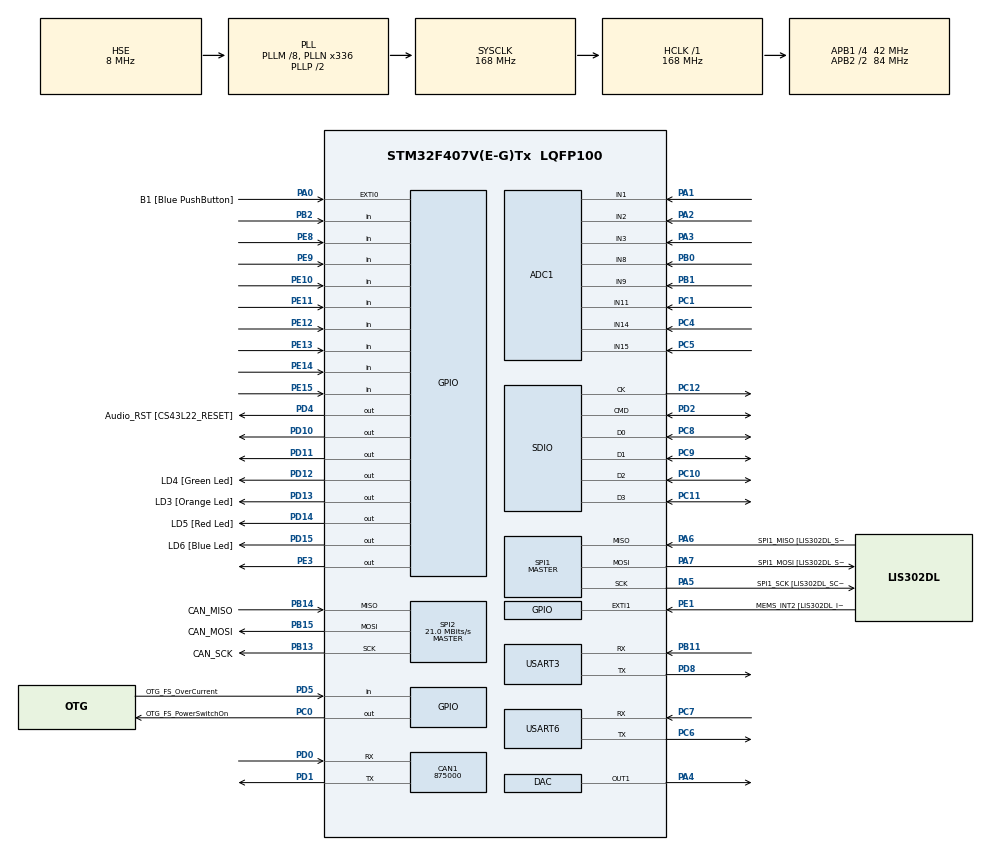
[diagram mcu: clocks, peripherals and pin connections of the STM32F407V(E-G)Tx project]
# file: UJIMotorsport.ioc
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ADC1.Channel-16\#ChannelRegularConversion=ADC_CHANNEL_1
ADC1.Channel-17\#ChannelRegularConversion=ADC_CHANNEL_2
ADC1.Channel-18\#ChannelRegularConversion=ADC_CHANNEL_3
ADC1.Channel-19\#ChannelRegularConversion=ADC_CHANNEL_8
ADC1.Channel-20\#ChannelRegularConversion=ADC_CHANNEL_9
ADC1.Channel-21\#ChannelRegularConversion=ADC_CHANNEL_11
ADC1.Channel-22\#ChannelRegularConversion=ADC_CHANNEL_14
ADC1.Channel-23\#ChannelRegularConversion=ADC_CHANNEL_15
ADC1.Channel-24\#ChannelRegularConversion=ADC_CHANNEL_TEMPSENSOR
ADC1.Channel-25\#ChannelRegularConversion=ADC_CHANNEL_VREFINT
ADC1.Channel-26\#ChannelRegularConversion=ADC_CHANNEL_VBAT
ADC1.ContinuousConvMode=ENABLE
ADC1.DMAContinuousRequests=ENABLE
ADC1.NbrOfConversion=11
ADC1.NbrOfConversionFlag=1
ADC1.Rank-16\#ChannelRegularConversion=1
ADC1.Rank-17\#ChannelRegularConversion=2
ADC1.Rank-18\#ChannelRegularConversion=3
ADC1.Rank-19\#ChannelRegularConversion=4
ADC1.Rank-20\#ChannelRegularConversion=5
ADC1.Rank-21\#ChannelRegularConversion=6
ADC1.Rank-22\#ChannelRegularConversion=7
ADC1.Rank-23\#ChannelRegularConversion=8
ADC1.Rank-24\#ChannelRegularConversion=9
ADC1.Rank-25\#ChannelRegularConversion=10
ADC1.Rank-26\#ChannelRegularConversion=11
ADC1.SamplingTime-16\#ChannelRegularConversion=ADC_SAMPLETIME_3CYCLES
ADC1.SamplingTime-17\#ChannelRegularConversion=ADC_SAMPLETIME_3CYCLES
ADC1.SamplingTime-18\#ChannelRegularConversion=ADC_SAMPLETIME_3CYCLES
ADC1.SamplingTime-19\#ChannelRegularConversion=ADC_SAMPLETIME_3CYCLES
ADC1.SamplingTime-20\#ChannelRegularConversion=ADC_SAMPLETIME_3CYCLES
ADC1.SamplingTime-21\#ChannelRegularConversion=ADC_SAMPLETIME_3CYCLES
ADC1.SamplingTime-22\#ChannelRegularConversion=ADC_SAMPLETIME_3CYCLES
ADC1.SamplingTime-23\#ChannelRegularConversion=ADC_SAMPLETIME_3CYCLES
ADC1.SamplingTime-24\#ChannelRegularConversion=ADC_SAMPLETIME_3CYCLES
ADC1.SamplingTime-25\#ChannelRegularConversion=ADC_SAMPLETIME_3CYCLES
ADC1.SamplingTime-26\#ChannelRegularConversion=ADC_SAMPLETIME_3CYCLES
ADC1.ScanConvMode=ENABLE
ADC1.master=1
CAN1.CalculateBaudRate=875000
CAN1.CalculateTimeBit=1142
CAN1.CalculateTimeQuantum=380.95238095238096
Dma.ADC1.0.Direction=DMA_PERIPH_TO_MEMORY
Dma.ADC1.0.FIFOMode=DMA_FIFOMODE_DISABLE
Dma.ADC1.0.Instance=DMA2_Stream0
Dma.ADC1.0.MemDataAlignment=DMA_MDATAALIGN_HALFWORD
Dma.ADC1.0.MemInc=DMA_MINC_ENABLE
Dma.ADC1.0.Mode=DMA_CIRCULAR
Dma.ADC1.0.PeriphDataAlignment=DMA_PDATAALIGN_HALFWORD
Dma.ADC1.0.PeriphInc=DMA_PINC_DISABLE
Dma.ADC1.0.Priority=DMA_PRIORITY_LOW
Dma.Request0=ADC1
FATFS.BSP.number=1
FATFS0.BSP.STBoard=false
FATFS0.BSP.api=Unknown
FATFS0.BSP.i2caddr=0
FATFS0.BSP.instance=PB2
FATFS0.BSP.ip=GPIO
FATFS0.BSP.mode=Input
FATFS0.BSP.name=Detect_SDIO
FATFS0.BSP.solution=PB2
FREERTOS.INCLUDE_vTaskDelayUntil=1
FREERTOS.Tasks01=defaultTask,0,128,StartDefaultTask,Default,NULL,Dynamic,NULL,NULL
FREERTOS.configENABLE_FPU=1
FREERTOS.configTOTAL_HEAP_SIZE=32768
FREERTOS.configUSE_NEWLIB_REENTRANT=1
Mcu.Family=STM32F4
Mcu.Name=STM32F407V(E-G)Tx
Mcu.Package=LQFP100
NVIC.DMA2_Stream0_IRQn=true\:5\:0\:false\:false\:true\:true\:false\:true
NVIC.PriorityGroup=NVIC_PRIORITYGROUP_4
NVIC.TIM6_DAC_IRQn=true\:15\:0\:false\:false\:true\:false\:false\:true
NVIC.TimeBase=TIM6_DAC_IRQn
NVIC.TimeBaseIP=TIM6
PA0-WKUP.GPIO_Label=B1 [Blue PushButton]
PA0-WKUP.GPIO_ModeDefaultEXTI=GPIO_MODE_EVT_RISING
PA0-WKUP.GPIO_PuPd=GPIO_NOPULL
PA0-WKUP.Signal=GPXTI0
PA1.Signal=ADCx_IN1
PA10.GPIO_Label=OTG_FS_ID
PA10.GPIO_Mode=GPIO_MODE_AF_PP
PA10.GPIO_PuPd=GPIO_NOPULL
PA10.GPIO_Speed=GPIO_SPEED_FREQ_LOW
PA10.Signal=USB_OTG_FS_ID
PA11.GPIO_Label=OTG_FS_DM
PA11.GPIO_Mode=GPIO_MODE_AF_PP
PA11.GPIO_PuPd=GPIO_NOPULL
PA11.GPIO_Speed=GPIO_SPEED_FREQ_LOW
PA11.Signal=USB_OTG_FS_DM
PA12.GPIO_Label=OTG_FS_DP
PA12.GPIO_Mode=GPIO_MODE_AF_PP
PA12.GPIO_PuPd=GPIO_NOPULL
PA12.GPIO_Speed=GPIO_SPEED_FREQ_LOW
PA12.Signal=USB_OTG_FS_DP
PA13.GPIO_Label=SWDIO
PA13.Mode=Serial_Wire
PA13.Signal=SYS_JTMS-SWDIO
PA14.GPIO_Label=SWCLK
PA14.Mode=Serial_Wire
PA14.Signal=SYS_JTCK-SWCLK
PA2.Signal=ADCx_IN2
PA3.Signal=ADCx_IN3
PA4.Signal=COMP_DAC1_group
PA5.GPIO_Label=SPI1_SCK [LIS302DL_SCL/SPC]
PA5.GPIO_Mode=GPIO_MODE_AF_PP
PA5.GPIO_PuPd=GPIO_NOPULL
PA5.GPIO_Speed=GPIO_SPEED_FREQ_LOW
PA5.Mode=Full_Duplex_Master
PA5.Signal=SPI1_SCK
PA6.GPIO_Label=SPI1_MISO [LIS302DL_SDO]
PA6.GPIO_Mode=GPIO_MODE_AF_PP
PA6.GPIO_PuPd=GPIO_NOPULL
PA6.GPIO_Speed=GPIO_SPEED_FREQ_LOW
PA6.Mode=Full_Duplex_Master
PA6.Signal=SPI1_MISO
PA7.GPIO_Label=SPI1_MOSI [LIS302DL_SDA/SDI/SDO]
PA7.GPIO_Mode=GPIO_MODE_AF_PP
PA7.GPIO_PuPd=GPIO_NOPULL
PA7.GPIO_Speed=GPIO_SPEED_FREQ_LOW
PA7.Mode=Full_Duplex_Master
PA7.Signal=SPI1_MOSI
PA9.GPIO_Label=VBUS_FS
PA9.GPIO_Mode=GPIO_MODE_INPUT
PA9.GPIO_PuPd=GPIO_NOPULL
PA9.Signal=USB_OTG_FS_VBUS
PB0.Signal=ADCx_IN8
PB1.Signal=ADCx_IN9
PB10.GPIO_Label=CLK_IN [MP45DT02_CLK]
PB10.GPIO_Mode=GPIO_MODE_AF_PP
PB10.GPIO_PuPd=GPIO_NOPULL
PB10.GPIO_Speed=GPIO_SPEED_FREQ_LOW
PB10.Signal=I2S2_CK
PB11.Mode=Asynchronous
PB11.Signal=USART3_RX
PB13.GPIO_Label=CAN_SCK
PB13.Mode=Full_Duplex_Master
PB13.Signal=SPI2_SCK
PB14.GPIO_Label=CAN_MISO
PB14.Mode=Full_Duplex_Master
PB14.Signal=SPI2_MISO
PB15.GPIO_Label=CAN_MOSI
PB15.Mode=Full_Duplex_Master
PB15.Signal=SPI2_MOSI
PB2.Signal=GPIO_Input
PB3.GPIO_Label=SWO
PB3.Signal=SYS_JTDO-SWO
PC0.GPIO_Label=OTG_FS_PowerSwitchOn
PC0.GPIO_PuPd=GPIO_NOPULL
PC0.GPIO_Speed=GPIO_SPEED_FREQ_LOW
PC0.PinState=GPIO_PIN_SET
PC0.Signal=GPIO_Output
PC1.Signal=ADCx_IN11
PC10.Mode=SD_4_bits_Wide_bus
PC10.Signal=SDIO_D2
PC11.Mode=SD_4_bits_Wide_bus
PC11.Signal=SDIO_D3
PC12.Mode=SD_4_bits_Wide_bus
PC12.Signal=SDIO_CK
PC14-OSC32_IN.GPIO_Label=PC14-OSC32_IN
PC14-OSC32_IN.Mode=LSE-External-Oscillator
PC14-OSC32_IN.Signal=RCC_OSC32_IN
PC15-OSC32_OUT.GPIO_Label=PC15-OSC32_OUT
PC15-OSC32_OUT.Mode=LSE-External-Oscillator
PC15-OSC32_OUT.Signal=RCC_OSC32_OUT
PC3.GPIO_Label=PDM_OUT [MP45DT02_DOUT]
PC3.GPIO_Mode=GPIO_MODE_AF_PP
PC3.GPIO_PuPd=GPIO_NOPULL
PC3.GPIO_Speed=GPIO_SPEED_FREQ_LOW
PC3.Signal=I2S2_SD
PC4.Signal=ADCx_IN14
PC5.Signal=ADCx_IN15
PC6.Mode=Asynchronous
PC6.Signal=USART6_TX
PC7.Mode=Asynchronous
PC7.Signal=USART6_RX
PC8.Mode=SD_4_bits_Wide_bus
PC8.Signal=SDIO_D0
PC9.Mode=SD_4_bits_Wide_bus
PC9.Signal=SDIO_D1
PD0.Mode=CAN_Activate
PD0.Signal=CAN1_RX
PD1.Mode=CAN_Activate
PD1.Signal=CAN1_TX
PD10.Signal=GPIO_Output
PD11.Signal=GPIO_Output
PD12.GPIO_Label=LD4 [Green Led]
PD12.GPIO_PuPd=GPIO_NOPULL
PD12.GPIO_Speed=GPIO_SPEED_FREQ_LOW
PD12.Signal=GPIO_Output
PD13.GPIO_Label=LD3 [Orange Led]
PD13.GPIO_PuPd=GPIO_NOPULL
PD13.GPIO_Speed=GPIO_SPEED_FREQ_LOW
PD13.Signal=GPIO_Output
PD14.GPIO_Label=LD5 [Red Led]
PD14.GPIO_PuPd=GPIO_NOPULL
PD14.GPIO_Speed=GPIO_SPEED_FREQ_LOW
PD14.Signal=GPIO_Output
PD15.GPIO_Label=LD6 [Blue Led]
PD15.GPIO_PuPd=GPIO_NOPULL
PD15.GPIO_Speed=GPIO_SPEED_FREQ_LOW
PD15.Signal=GPIO_Output
PD2.Mode=SD_4_bits_Wide_bus
PD2.Signal=SDIO_CMD
PD4.GPIO_Label=Audio_RST [CS43L22_RESET]
PD4.GPIO_PuPd=GPIO_NOPULL
PD4.GPIO_Speed=GPIO_SPEED_FREQ_LOW
PD4.Signal=GPIO_Output
PD5.GPIO_Label=OTG_FS_OverCurrent
PD5.GPIO_Mode=GPIO_MODE_INPUT
PD5.GPIO_PuPd=GPIO_NOPULL
PD5.Signal=GPIO_Input
PD8.Mode=Asynchronous
PD8.Signal=USART3_TX
PE1.GPIO_Label=MEMS_INT2 [LIS302DL_INT2]
PE1.GPIO_ModeDefaultEXTI=GPIO_MODE_EVT_RISING
PE1.GPIO_PuPd=GPIO_NOPULL
PE1.Signal=GPXTI1
PE10.Signal=GPIO_Input
PE11.Signal=GPIO_Input
PE12.Signal=GPIO_Input
PE13.Signal=GPIO_Input
PE14.Signal=GPIO_Input
PE15.Signal=GPIO_Input
PE3.Signal=GPIO_Output
PE8.Signal=GPIO_Input
PE9.Signal=GPIO_Input
PH0-OSC_IN.GPIO_Label=PH0-OSC_IN
PH0-OSC_IN.Mode=HSE-External-Oscillator
PH0-OSC_IN.Signal=RCC_OSC_IN
PH1-OSC_OUT.GPIO_Label=PH1-OSC_OUT
PH1-OSC_OUT.Mode=HSE-External-Oscillator
PH1-OSC_OUT.Signal=RCC_OSC_OUT
ProjectManager.HeapSize=0x200
ProjectManager.StackSize=0x400
ProjectManager.TargetToolchain=STM32CubeIDE
RCC.48MHZClocksFreq_Value=48000000
RCC.AHBFreq_Value=168000000
RCC.APB1CLKDivider=RCC_HCLK_DIV4
RCC.APB1Freq_Value=42000000
RCC.APB1TimFreq_Value=84000000
RCC.APB2CLKDivider=RCC_HCLK_DIV2
RCC.APB2Freq_Value=84000000
RCC.APB2TimFreq_Value=168000000
RCC.CortexFreq_Value=168000000
RCC.HCLKFreq_Value=168000000
RCC.HSE_VALUE=8000000
RCC.HSI_VALUE=16000000
RCC.PLLM=8
RCC.PLLN=336
RCC.PLLQ=7
RCC.PLLSourceVirtual=RCC_PLLSOURCE_HSE
RCC.SYSCLKFreq_VALUE=168000000
RCC.SYSCLKSource=RCC_SYSCLKSOURCE_PLLCLK
RCC.VCOOutputFreq_Value=336000000
SH.ADCx_IN1.0=ADC1_IN1,IN1
SH.ADCx_IN11.0=ADC1_IN11,IN11
SH.ADCx_IN14.0=ADC1_IN14,IN14
SH.ADCx_IN15.0=ADC1_IN15,IN15
SH.ADCx_IN2.0=ADC1_IN2,IN2
SH.ADCx_IN3.0=ADC1_IN3,IN3
SH.ADCx_IN8.0=ADC1_IN8,IN8
SH.ADCx_IN9.0=ADC1_IN9,IN9
SH.COMP_DAC1_group.0=DAC_OUT1,DAC_OUT1
SPI1.BaudRatePrescaler-Full_Duplex_Master=SPI_BAUDRATEPRESCALER_2
SPI1.CalculateBaudRate-Full_Duplex_Master=42.0 MBits/s
SPI1.Direction=SPI_DIRECTION_2LINES
SPI1.Mode=SPI_MODE_MASTER
SPI1.Mode-Full_Duplex_Master=SPI_MODE_MASTER
SPI1.VirtualType=VM_MASTER
SPI2.CalculateBaudRate=21.0 MBits/s
SPI2.Direction=SPI_DIRECTION_2LINES
SPI2.Mode=SPI_MODE_MASTER
SPI2.VirtualType=VM_MASTER
USART3.VirtualMode=VM_ASYNC
USART6.VirtualMode=VM_ASYNC
VP_ADC1_TempSens_Input.Mode=IN-TempSens
VP_ADC1_Vbat_Input.Mode=IN-Vbat
VP_ADC1_Vref_Input.Mode=IN-Vrefint
VP_CRC_VS_CRC.Mode=CRC_Activate
VP_FATFS_VS_SDIO.Mode=SDIO
VP_FREERTOS_VS_CMSIS_V1.Mode=CMSIS_V1
VP_SYS_VS_tim6.Mode=TIM6
board=STM32F407G-DISC1

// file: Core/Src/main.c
/* USER CODE BEGIN Header */
/**
  ******************************************************************************
  * @file           : main.c
  * @brief          : Main program body
  ******************************************************************************
  * @attention
  *
  * Copyright (c) 2021 STMicroelectronics.
  * All rights reserved.
  *
  * This software is licensed under terms that can be found in the LICENSE file
  * in the root directory of this software component.
  * If no LICENSE file comes with this software, it is provided AS-IS.
  *
  ******************************************************************************
  */
/* USER CODE END Header */
#include "main.h"
#include "cmsis_os.h"
#include "fatfs.h"

/* USER CODE BEGIN Includes */
#include "UJI/SecondMain.h"

/* USER CODE END Includes */

ADC_HandleTypeDef hadc1;
DMA_HandleTypeDef hdma_adc1;

CAN_HandleTypeDef hcan1;

CRC_HandleTypeDef hcrc;

DAC_HandleTypeDef hdac;

SD_HandleTypeDef hsd;

SPI_HandleTypeDef hspi1;
SPI_HandleTypeDef hspi2;

UART_HandleTypeDef huart3;
UART_HandleTypeDef huart6;

osThreadId defaultTaskHandle;

void SystemClock_Config(void);
static void MX_GPIO_Init(void);
static void MX_SPI1_Init(void);
static void MX_DAC_Init(void);
static void MX_CAN1_Init(void);
static void MX_SPI2_Init(void);
static void MX_USART3_UART_Init(void);
static void MX_USART6_UART_Init(void);
static void MX_CRC_Init(void);
static void MX_SDIO_SD_Init(void);
static void MX_DMA_Init(void);
static void MX_ADC1_Init(void);
void StartDefaultTask(void const * argument);

int main(void)
{

  /* MCU Configuration--------------------------------------------------------*/

  /* Reset of all peripherals, Initializes the Flash interface and the Systick. */
  HAL_Init();

  /* Configure the system clock */
  SystemClock_Config();

  /* Initialize all configured peripherals */
  MX_GPIO_Init();
  MX_SPI1_Init();
  MX_DAC_Init();
  MX_CAN1_Init();
  MX_SPI2_Init();
  MX_USART3_UART_Init();
  MX_USART6_UART_Init();
  MX_CRC_Init();
  MX_SDIO_SD_Init();
  MX_FATFS_Init();
  MX_DMA_Init();
  MX_ADC1_Init();
  /* USER CODE BEGIN 2 */
  // From here we abdup the workflow
  SecondMain();
  /* USER CODE END 2 */

  /* Create the thread(s) */
  /* definition and creation of defaultTask */
  osThreadDef(defaultTask, StartDefaultTask, osPriorityNormal, 0, 128);
  defaultTaskHandle = osThreadCreate(osThread(defaultTask), NULL);

  /* Start scheduler */
  osKernelStart();

  /* We should never get here as control is now taken by the scheduler */
  /* Infinite loop */
  while (1)
  {

  }
}

void SystemClock_Config(void)
{
  RCC_OscInitTypeDef RCC_OscInitStruct = {0};
  RCC_ClkInitTypeDef RCC_ClkInitStruct = {0};

  /** Configure the main internal regulator output voltage
  */
  __HAL_RCC_PWR_CLK_ENABLE();
  __HAL_PWR_VOLTAGESCALING_CONFIG(PWR_REGULATOR_VOLTAGE_SCALE1);
  /** Initializes the RCC Oscillators according to the specified parameters
  * in the RCC_OscInitTypeDef structure.
  */
  RCC_OscInitStruct.OscillatorType = RCC_OSCILLATORTYPE_HSE;
  RCC_OscInitStruct.HSEState = RCC_HSE_ON;
  RCC_OscInitStruct.PLL.PLLState = RCC_PLL_ON;
  RCC_OscInitStruct.PLL.PLLSource = RCC_PLLSOURCE_HSE;
  RCC_OscInitStruct.PLL.PLLM = 8;
  RCC_OscInitStruct.PLL.PLLN = 336;
  RCC_OscInitStruct.PLL.PLLP = RCC_PLLP_DIV2;
  RCC_OscInitStruct.PLL.PLLQ = 7;
  if (HAL_RCC_OscConfig(&RCC_OscInitStruct) != HAL_OK)
  {
    Error_Handler();
  }
  /** Initializes the CPU, AHB and APB buses clocks
  */
  RCC_ClkInitStruct.ClockType = RCC_CLOCKTYPE_HCLK|RCC_CLOCKTYPE_SYSCLK
                              |RCC_CLOCKTYPE_PCLK1|RCC_CLOCKTYPE_PCLK2;
  RCC_ClkInitStruct.SYSCLKSource = RCC_SYSCLKSOURCE_PLLCLK;
  RCC_ClkInitStruct.AHBCLKDivider = RCC_SYSCLK_DIV1;
  RCC_ClkInitStruct.APB1CLKDivider = RCC_HCLK_DIV4;
  RCC_ClkInitStruct.APB2CLKDivider = RCC_HCLK_DIV2;

  if (HAL_RCC_ClockConfig(&RCC_ClkInitStruct, FLASH_LATENCY_5) != HAL_OK)
  {
    Error_Handler();
  }
}

static void MX_ADC1_Init(void)
{

  ADC_ChannelConfTypeDef sConfig = {0};

  /** Configure the global features of the ADC (Clock, Resolution, Data Alignment and number of conversion)
  */
  hadc1.Instance = ADC1;
  hadc1.Init.ClockPrescaler = ADC_CLOCK_SYNC_PCLK_DIV4;
  hadc1.Init.Resolution = ADC_RESOLUTION_12B;
  hadc1.Init.ScanConvMode = ENABLE;
  hadc1.Init.ContinuousConvMode = ENABLE;
  hadc1.Init.DiscontinuousConvMode = DISABLE;
  hadc1.Init.ExternalTrigConvEdge = ADC_EXTERNALTRIGCONVEDGE_NONE;
  hadc1.Init.ExternalTrigConv = ADC_SOFTWARE_START;
  hadc1.Init.DataAlign = ADC_DATAALIGN_RIGHT;
  hadc1.Init.NbrOfConversion = 11;
  hadc1.Init.DMAContinuousRequests = ENABLE;
  hadc1.Init.EOCSelection = ADC_EOC_SINGLE_CONV;
  if (HAL_ADC_Init(&hadc1) != HAL_OK)
  {
    Error_Handler();
  }
  /** Configure for the selected ADC regular channel its corresponding rank in the sequencer and its sample time.
  */
  sConfig.Channel = ADC_CHANNEL_1;
  sConfig.Rank = 1;
  sConfig.SamplingTime = ADC_SAMPLETIME_3CYCLES;
  if (HAL_ADC_ConfigChannel(&hadc1, &sConfig) != HAL_OK)
  {
    Error_Handler();
  }
  /** Configure for the selected ADC regular channel its corresponding rank in the sequencer and its sample time.
  */
  sConfig.Channel = ADC_CHANNEL_2;
  sConfig.Rank = 2;
  if (HAL_ADC_ConfigChannel(&hadc1, &sConfig) != HAL_OK)
  {
    Error_Handler();
  }
  /** Configure for the selected ADC regular channel its corresponding rank in the sequencer and its sample time.
  */
  sConfig.Channel = ADC_CHANNEL_3;
  sConfig.Rank = 3;
  if (HAL_ADC_ConfigChannel(&hadc1, &sConfig) != HAL_OK)
  {
    Error_Handler();
  }
  /** Configure for the selected ADC regular channel its corresponding rank in the sequencer and its sample time.
  */
  sConfig.Channel = ADC_CHANNEL_8;
  sConfig.Rank = 4;
  if (HAL_ADC_ConfigChannel(&hadc1, &sConfig) != HAL_OK)
  {
    Error_Handler();
  }
  /** Configure for the selected ADC regular channel its corresponding rank in the sequencer and its sample time.
  */
  sConfig.Channel = ADC_CHANNEL_9;
  sConfig.Rank = 5;
  if (HAL_ADC_ConfigChannel(&hadc1, &sConfig) != HAL_OK)
  {
    Error_Handler();
  }
  /** Configure for the selected ADC regular channel its corresponding rank in the sequencer and its sample time.
  */
  sConfig.Channel = ADC_CHANNEL_11;
  sConfig.Rank = 6;
  if (HAL_ADC_ConfigChannel(&hadc1, &sConfig) != HAL_OK)
  {
    Error_Handler();
  }
  /** Configure for the selected ADC regular channel its corresponding rank in the sequencer and its sample time.
  */
  sConfig.Channel = ADC_CHANNEL_14;
  sConfig.Rank = 7;
  if (HAL_ADC_ConfigChannel(&hadc1, &sConfig) != HAL_OK)
  {
    Error_Handler();
  }
  /** Configure for the selected ADC regular channel its corresponding rank in the sequencer and its sample time.
  */
  sConfig.Channel = ADC_CHANNEL_15;
  sConfig.Rank = 8;
  if (HAL_ADC_ConfigChannel(&hadc1, &sConfig) != HAL_OK)
  {
    Error_Handler();
  }
  /** Configure for the selected ADC regular channel its corresponding rank in the sequencer and its sample time.
  */
  sConfig.Channel = ADC_CHANNEL_TEMPSENSOR;
  sConfig.Rank = 9;
  if (HAL_ADC_ConfigChannel(&hadc1, &sConfig) != HAL_OK)
  {
    Error_Handler();
  }
  /** Configure for the selected ADC regular channel its corresponding rank in the sequencer and its sample time.
  */
  sConfig.Channel = ADC_CHANNEL_VREFINT;
  sConfig.Rank = 10;
  if (HAL_ADC_ConfigChannel(&hadc1, &sConfig) != HAL_OK)
  {
    Error_Handler();
  }
  /** Configure for the selected ADC regular channel its corresponding rank in the sequencer and its sample time.
  */
  sConfig.Channel = ADC_CHANNEL_VBAT;
  sConfig.Rank = 11;
  if (HAL_ADC_ConfigChannel(&hadc1, &sConfig) != HAL_OK)
  {
    Error_Handler();
  }

}

static void MX_CAN1_Init(void)
{

  hcan1.Instance = CAN1;
  hcan1.Init.Prescaler = 16;
  hcan1.Init.Mode = CAN_MODE_NORMAL;
  hcan1.Init.SyncJumpWidth = CAN_SJW_1TQ;
  hcan1.Init.TimeSeg1 = CAN_BS1_1TQ;
  hcan1.Init.TimeSeg2 = CAN_BS2_1TQ;
  hcan1.Init.TimeTriggeredMode = DISABLE;
  hcan1.Init.AutoBusOff = DISABLE;
  hcan1.Init.AutoWakeUp = DISABLE;
  hcan1.Init.AutoRetransmission = DISABLE;
  hcan1.Init.ReceiveFifoLocked = DISABLE;
  hcan1.Init.TransmitFifoPriority = DISABLE;
  if (HAL_CAN_Init(&hcan1) != HAL_OK)
  {
    Error_Handler();
  }

}

static void MX_CRC_Init(void)
{

  hcrc.Instance = CRC;
  if (HAL_CRC_Init(&hcrc) != HAL_OK)
  {
    Error_Handler();
  }

}

static void MX_DAC_Init(void)
{

  DAC_ChannelConfTypeDef sConfig = {0};

  /** DAC Initialization
  */
  hdac.Instance = DAC;
  if (HAL_DAC_Init(&hdac) != HAL_OK)
  {
    Error_Handler();
  }
  /** DAC channel OUT1 config
  */
  sConfig.DAC_Trigger = DAC_TRIGGER_NONE;
  sConfig.DAC_OutputBuffer = DAC_OUTPUTBUFFER_ENABLE;
  if (HAL_DAC_ConfigChannel(&hdac, &sConfig, DAC_CHANNEL_1) != HAL_OK)
  {
    Error_Handler();
  }

}

static void MX_SDIO_SD_Init(void)
{

  hsd.Instance = SDIO;
  hsd.Init.ClockEdge = SDIO_CLOCK_EDGE_RISING;
  hsd.Init.ClockBypass = SDIO_CLOCK_BYPASS_DISABLE;
  hsd.Init.ClockPowerSave = SDIO_CLOCK_POWER_SAVE_DISABLE;
  hsd.Init.BusWide = SDIO_BUS_WIDE_1B;
  hsd.Init.HardwareFlowControl = SDIO_HARDWARE_FLOW_CONTROL_DISABLE;
  hsd.Init.ClockDiv = 0;

}

static void MX_SPI1_Init(void)
{

  /* SPI1 parameter configuration*/
  hspi1.Instance = SPI1;
  hspi1.Init.Mode = SPI_MODE_MASTER;
  hspi1.Init.Direction = SPI_DIRECTION_2LINES;
  hspi1.Init.DataSize = SPI_DATASIZE_8BIT;
  hspi1.Init.CLKPolarity = SPI_POLARITY_LOW;
  hspi1.Init.CLKPhase = SPI_PHASE_1EDGE;
  hspi1.Init.NSS = SPI_NSS_SOFT;
  hspi1.Init.BaudRatePrescaler = SPI_BAUDRATEPRESCALER_2;
  hspi1.Init.FirstBit = SPI_FIRSTBIT_MSB;
  hspi1.Init.TIMode = SPI_TIMODE_DISABLE;
  hspi1.Init.CRCCalculation = SPI_CRCCALCULATION_DISABLE;
  hspi1.Init.CRCPolynomial = 10;
  if (HAL_SPI_Init(&hspi1) != HAL_OK)
  {
    Error_Handler();
  }

}

static void MX_SPI2_Init(void)
{

  /* SPI2 parameter configuration*/
  hspi2.Instance = SPI2;
  hspi2.Init.Mode = SPI_MODE_MASTER;
  hspi2.Init.Direction = SPI_DIRECTION_2LINES;
  hspi2.Init.DataSize = SPI_DATASIZE_8BIT;
  hspi2.Init.CLKPolarity = SPI_POLARITY_LOW;
  hspi2.Init.CLKPhase = SPI_PHASE_1EDGE;
  hspi2.Init.NSS = SPI_NSS_SOFT;
  hspi2.Init.BaudRatePrescaler = SPI_BAUDRATEPRESCALER_2;
  hspi2.Init.FirstBit = SPI_FIRSTBIT_MSB;
  hspi2.Init.TIMode = SPI_TIMODE_DISABLE;
  hspi2.Init.CRCCalculation = SPI_CRCCALCULATION_DISABLE;
  hspi2.Init.CRCPolynomial = 10;
  if (HAL_SPI_Init(&hspi2) != HAL_OK)
  {
    Error_Handler();
  }

}

static void MX_USART3_UART_Init(void)
{

  huart3.Instance = USART3;
  huart3.Init.BaudRate = 115200;
  huart3.Init.WordLength = UART_WORDLENGTH_8B;
  huart3.Init.StopBits = UART_STOPBITS_1;
  huart3.Init.Parity = UART_PARITY_NONE;
  huart3.Init.Mode = UART_MODE_TX_RX;
  huart3.Init.HwFlowCtl = UART_HWCONTROL_NONE;
  huart3.Init.OverSampling = UART_OVERSAMPLING_16;
  if (HAL_UART_Init(&huart3) != HAL_OK)
  {
    Error_Handler();
  }

}

static void MX_USART6_UART_Init(void)
{

  huart6.Instance = USART6;
  huart6.Init.BaudRate = 115200;
  huart6.Init.WordLength = UART_WORDLENGTH_8B;
  huart6.Init.StopBits = UART_STOPBITS_1;
  huart6.Init.Parity = UART_PARITY_NONE;
  huart6.Init.Mode = UART_MODE_TX_RX;
  huart6.Init.HwFlowCtl = UART_HWCONTROL_NONE;
  huart6.Init.OverSampling = UART_OVERSAMPLING_16;
  if (HAL_UART_Init(&huart6) != HAL_OK)
  {
    Error_Handler();
  }

}

static void MX_DMA_Init(void)
{

  /* DMA controller clock enable */
  __HAL_RCC_DMA2_CLK_ENABLE();

  /* DMA interrupt init */
  /* DMA2_Stream0_IRQn interrupt configuration */
  HAL_NVIC_SetPriority(DMA2_Stream0_IRQn, 5, 0);
  HAL_NVIC_EnableIRQ(DMA2_Stream0_IRQn);

}

static void MX_GPIO_Init(void)
{
  GPIO_InitTypeDef GPIO_InitStruct = {0};

  /* GPIO Ports Clock Enable */
  __HAL_RCC_GPIOE_CLK_ENABLE();
  __HAL_RCC_GPIOC_CLK_ENABLE();
  __HAL_RCC_GPIOH_CLK_ENABLE();
  __HAL_RCC_GPIOA_CLK_ENABLE();
  __HAL_RCC_GPIOB_CLK_ENABLE();
  __HAL_RCC_GPIOD_CLK_ENABLE();

  /*Configure GPIO pin Output Level */
  HAL_GPIO_WritePin(GPIOE, GPIO_PIN_3, GPIO_PIN_RESET);

  /*Configure GPIO pin Output Level */
  HAL_GPIO_WritePin(OTG_FS_PowerSwitchOn_GPIO_Port, OTG_FS_PowerSwitchOn_Pin, GPIO_PIN_SET);

  /*Configure GPIO pin Output Level */
  HAL_GPIO_WritePin(GPIOD, GPIO_PIN_10|GPIO_PIN_11|LD4_Pin|LD3_Pin
                          |LD5_Pin|LD6_Pin|Audio_RST_Pin, GPIO_PIN_RESET);

  /*Configure GPIO pin : PE3 */
  GPIO_InitStruct.Pin = GPIO_PIN_3;
  GPIO_InitStruct.Mode = GPIO_MODE_OUTPUT_PP;
  GPIO_InitStruct.Pull = GPIO_NOPULL;
  GPIO_InitStruct.Speed = GPIO_SPEED_FREQ_LOW;
  HAL_GPIO_Init(GPIOE, &GPIO_InitStruct);

  /*Configure GPIO pin : OTG_FS_PowerSwitchOn_Pin */
  GPIO_InitStruct.Pin = OTG_FS_PowerSwitchOn_Pin;
  GPIO_InitStruct.Mode = GPIO_MODE_OUTPUT_PP;
  GPIO_InitStruct.Pull = GPIO_NOPULL;
  GPIO_InitStruct.Speed = GPIO_SPEED_FREQ_LOW;
  HAL_GPIO_Init(OTG_FS_PowerSwitchOn_GPIO_Port, &GPIO_InitStruct);

  /*Configure GPIO pin : PDM_OUT_Pin */
  GPIO_InitStruct.Pin = PDM_OUT_Pin;
  GPIO_InitStruct.Mode = GPIO_MODE_AF_PP;
  GPIO_InitStruct.Pull = GPIO_NOPULL;
  GPIO_InitStruct.Speed = GPIO_SPEED_FREQ_LOW;
  GPIO_InitStruct.Alternate = GPIO_AF5_SPI2;
  HAL_GPIO_Init(PDM_OUT_GPIO_Port, &GPIO_InitStruct);

  /*Configure GPIO pin : B1_Pin */
  GPIO_InitStruct.Pin = B1_Pin;
  GPIO_InitStruct.Mode = GPIO_MODE_EVT_RISING;
  GPIO_InitStruct.Pull = GPIO_NOPULL;
  HAL_GPIO_Init(B1_GPIO_Port, &GPIO_InitStruct);

  /*Configure GPIO pin : PB2 */
  GPIO_InitStruct.Pin = GPIO_PIN_2;
  GPIO_InitStruct.Mode = GPIO_MODE_INPUT;
  GPIO_InitStruct.Pull = GPIO_NOPULL;
  HAL_GPIO_Init(GPIOB, &GPIO_InitStruct);

  /*Configure GPIO pins : PE8 PE9 PE10 PE11
                           PE12 PE13 PE14 PE15 */
  GPIO_InitStruct.Pin = GPIO_PIN_8|GPIO_PIN_9|GPIO_PIN_10|GPIO_PIN_11
                          |GPIO_PIN_12|GPIO_PIN_13|GPIO_PIN_14|GPIO_PIN_15;
  GPIO_InitStruct.Mode = GPIO_MODE_INPUT;
  GPIO_InitStruct.Pull = GPIO_NOPULL;
  HAL_GPIO_Init(GPIOE, &GPIO_InitStruct);

  /*Configure GPIO pin : CLK_IN_Pin */
  GPIO_InitStruct.Pin = CLK_IN_Pin;
  GPIO_InitStruct.Mode = GPIO_MODE_AF_PP;
  GPIO_InitStruct.Pull = GPIO_NOPULL;
  GPIO_InitStruct.Speed = GPIO_SPEED_FREQ_LOW;
  GPIO_InitStruct.Alternate = GPIO_AF5_SPI2;
  HAL_GPIO_Init(CLK_IN_GPIO_Port, &GPIO_InitStruct);

  /*Configure GPIO pins : PD10 PD11 LD4_Pin LD3_Pin
                           LD5_Pin LD6_Pin Audio_RST_Pin */
  GPIO_InitStruct.Pin = GPIO_PIN_10|GPIO_PIN_11|LD4_Pin|LD3_Pin
                          |LD5_Pin|LD6_Pin|Audio_RST_Pin;
  GPIO_InitStruct.Mode = GPIO_MODE_OUTPUT_PP;
  GPIO_InitStruct.Pull = GPIO_NOPULL;
  GPIO_InitStruct.Speed = GPIO_SPEED_FREQ_LOW;
  HAL_GPIO_Init(GPIOD, &GPIO_InitStruct);

  /*Configure GPIO pin : VBUS_FS_Pin */
  GPIO_InitStruct.Pin = VBUS_FS_Pin;
  GPIO_InitStruct.Mode = GPIO_MODE_INPUT;
  GPIO_InitStruct.Pull = GPIO_NOPULL;
  HAL_GPIO_Init(VBUS_FS_GPIO_Port, &GPIO_InitStruct);

  /*Configure GPIO pins : OTG_FS_ID_Pin OTG_FS_DM_Pin OTG_FS_DP_Pin */
  GPIO_InitStruct.Pin = OTG_FS_ID_Pin|OTG_FS_DM_Pin|OTG_FS_DP_Pin;
  GPIO_InitStruct.Mode = GPIO_MODE_AF_PP;
  GPIO_InitStruct.Pull = GPIO_NOPULL;
  GPIO_InitStruct.Speed = GPIO_SPEED_FREQ_LOW;
  GPIO_InitStruct.Alternate = GPIO_AF10_OTG_FS;
  HAL_GPIO_Init(GPIOA, &GPIO_InitStruct);

  /*Configure GPIO pin : OTG_FS_OverCurrent_Pin */
  GPIO_InitStruct.Pin = OTG_FS_OverCurrent_Pin;
  GPIO_InitStruct.Mode = GPIO_MODE_INPUT;
  GPIO_InitStruct.Pull = GPIO_NOPULL;
  HAL_GPIO_Init(OTG_FS_OverCurrent_GPIO_Port, &GPIO_InitStruct);

  /*Configure GPIO pin : MEMS_INT2_Pin */
  GPIO_InitStruct.Pin = MEMS_INT2_Pin;
  GPIO_InitStruct.Mode = GPIO_MODE_EVT_RISING;
  GPIO_InitStruct.Pull = GPIO_NOPULL;
  HAL_GPIO_Init(MEMS_INT2_GPIO_Port, &GPIO_InitStruct);

}

void StartDefaultTask(void const * argument)
{
  for(;;)
  {
    osDelay(1);
  }
}

void HAL_TIM_PeriodElapsedCallback(TIM_HandleTypeDef *htim)
{
  if (htim->Instance == TIM6) {
    HAL_IncTick();
  }
}

void Error_Handler(void)
{
  /* USER CODE BEGIN Error_Handler_Debug */
#ifdef DEBUG
	asm("BKPT #0");
#endif
  /* User can add his own implementation to report the HAL error return state */
  __disable_irq();
  while (1)
  {
  }
  /* USER CODE END Error_Handler_Debug */
}

#ifdef  USE_FULL_ASSERT
/**
  * @brief  Reports the name of the source file and the source line number
  *         where the assert_param error has occurred.
  * @param  file: pointer to the source file name
  * @param  line: assert_param error line source number
  * @retval None
  */
void assert_failed(uint8_t *file, uint32_t line)
{
  /* USER CODE BEGIN 6 */
  /* User can add his own implementation to report the file name and line number,
     ex: printf("Wrong parameters value: file %s on line %d\r\n", file, line) */
#ifdef DEBUG
	asm("BKPT #0");
#endif
  /* USER CODE END 6 */
}
#endif /* USE_FULL_ASSERT */
